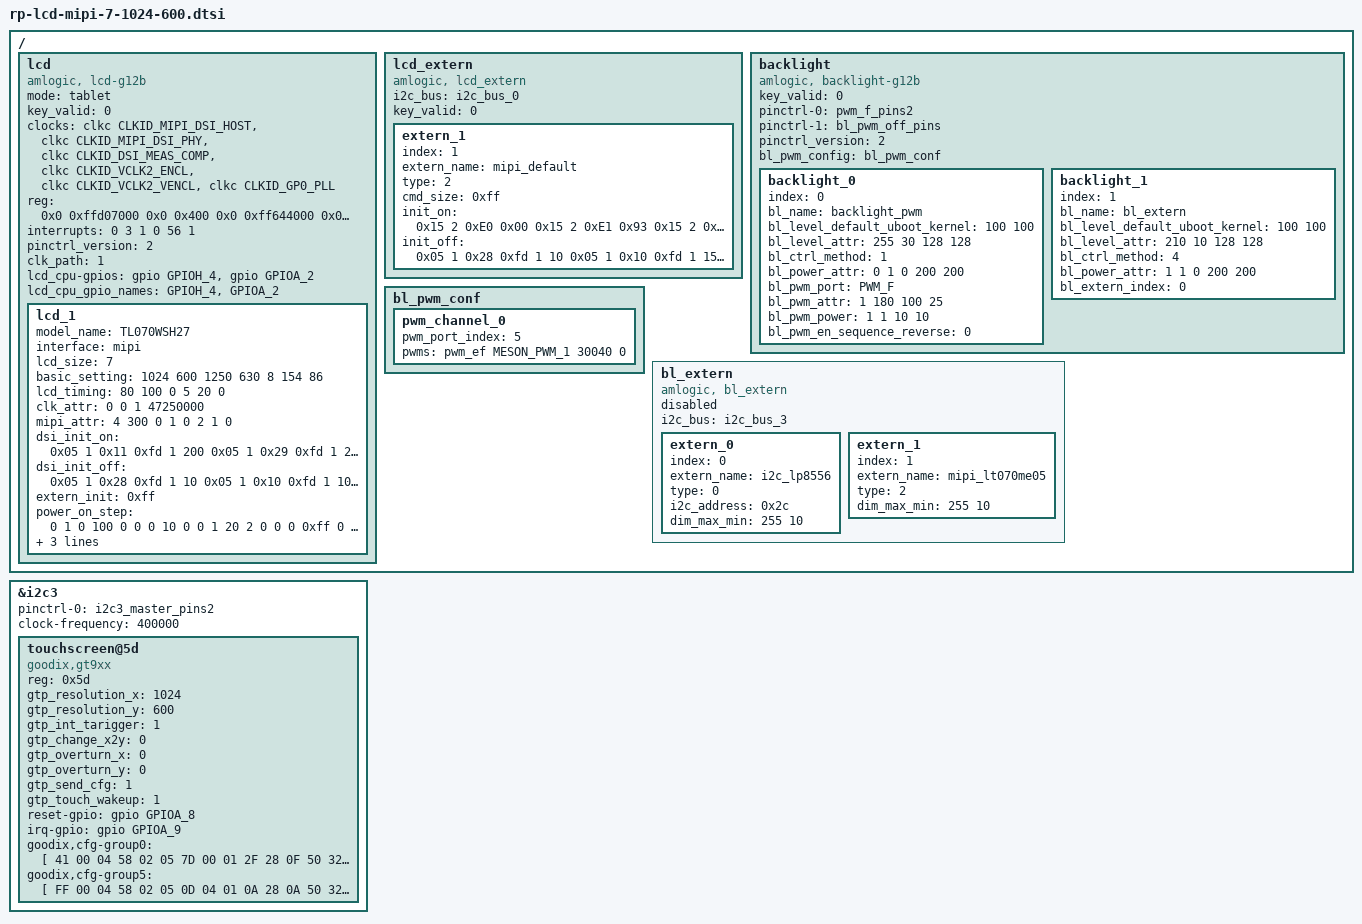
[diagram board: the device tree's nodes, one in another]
/*
 * arch/arm64/boot/dts/amlogic/mesong12b_skt-panel.dtsi
 *
 * Copyright (C) 2016 Amlogic, Inc. All rights reserved.
 *
 * This program is free software; you can redistribute it and/or modify
 * it under the terms of the GNU General Public License as published by
 * the Free Software Foundation; either version 2 of the License, or
 * (at your option) any later version.
 *
 * This program is distributed in the hope that it will be useful, but WITHOUT
 * ANY WARRANTY; without even the implied warranty of MERCHANTABILITY or
 * FITNESS FOR A PARTICULAR PURPOSE.  See the GNU General Public License for
 * more details.
 *
 */

/ {
	lcd{
		compatible = "amlogic, lcd-g12b";
		mode = "tablet";
		status = "okay";
		key_valid = <0>;
		clocks = <&clkc CLKID_MIPI_DSI_HOST
			&clkc CLKID_MIPI_DSI_PHY
			&clkc CLKID_DSI_MEAS_COMP
			&clkc CLKID_VCLK2_ENCL
			&clkc CLKID_VCLK2_VENCL
			&clkc CLKID_GP0_PLL>;
		clock-names = "dsi_host_gate",
			"dsi_phy_gate",
			"dsi_meas",
			"encl_top_gate",
			"encl_int_gate",
			"gp0_pll";
		reg = <0x0 0xffd07000 0x0 0x400    /* dsi_host */
			0x0 0xff644000 0x0 0x200>; /* dsi_phy */
		interrupts = <0 3 1
			0 56 1>;
		interrupt-names = "vsync","vsync2";
		pinctrl_version = <2>; /* for uboot */
		clk_path = <1>; /* default gp0 pll */

		/* power type:
		 *    (0=cpu_gpio, 1=pmu_gpio, 2=signal,3=extern, 0xff=ending)
		 * power index:
		 *    (point gpios_index, or extern_index,0xff=invalid)
		 * power value:(0=output low, 1=output high, 2=input)
		 * power delay:(unit in ms)
		 */
		lcd_cpu-gpios = <&gpio GPIOH_4 GPIO_ACTIVE_HIGH
				&gpio GPIOA_2 GPIO_ACTIVE_HIGH>;
		lcd_cpu_gpio_names = "GPIOH_4","GPIOA_2";


		lcd_1{
			model_name = "TL070WSH27";
			interface = "mipi";
			lcd_size = "7";
			basic_setting = <1024 600 /*h_active, v_active*/
				1250 630 /*h_period, v_period*/
				8 /*lcd_bits*/
				154 86>; /*screen_widht, screen_height*/
			lcd_timing = <80 100 0 /*hs_width, hs_bp, hs_pol*/
				5 20 0>; /*vs_width, vs_bp, vs_pol*/
			clk_attr = <0 /*fr_adj_type(0=clk, 1=htotal, 2=vtotal)*/
				0 /*clk_ss_level */
				1 /*clk_auto_generate*/
				47250000>; /*pixel_clk(unit in Hz)*/
			mipi_attr = <4 /*lane_num*/
				300 /*bit_rate_max(MHz)*/
				0 /*factor(*100, default 0 for auto)*/
				1 /*operation_mode_init(0=video, 1=command)*/
				0 /*operation_mode_display(0=video, 1=command)*/
				2 /*
				   *video_mode_type
				   *(0=sync_pulse,1=sync_event,2=burst)
				   */
				1 /*clk_always_hs(0=disable,1=enable)*/
				0>; /*phy_switch(0=auto,1=standard,2=slow)*/

			/* dsi_init: data_type, num, data... */
			dsi_init_on = <0x05 1 0x11
					0xfd 1 200  /*delay(ms)*/
					0x05 1 0x29
					0xfd 1 20   /*delay(ms)*/
					0xff 0>;    /*ending*/
			dsi_init_off = <0x05 1 0x28
					0xfd 1 10   /*delay(ms)*/
					0x05 1 0x10
					0xfd 1 10   /*delay(ms)*/
					0xff 0>;    /*ending*/
			extern_init = <0xff>; /*0xff for invalid*/

			/* power step: type, index, value, delay(ms) */
			power_on_step = <
				0 1 0 100
				0 0 0 10
				0 0 1 20
				2 0 0 0
				0xff 0 0 0>; /*ending*/
			power_off_step = <
				2 0 0 50
				0 0 0 10
				0 1 1 100
				0xff 0 0 0>; /*ending*/
			backlight_index = <0>;
		};
	};

	lcd_extern{
		compatible = "amlogic, lcd_extern";
		status = "okay";
		i2c_bus = "i2c_bus_0";
		key_valid = <0>;

		extern_1{
			index = <1>;
			extern_name = "mipi_default";/*P070ACB_FT*/
			status = "okay";
			type = <2>; /* 0=i2c, 1=spi, 2=mipi */
			cmd_size = <0xff>;
			init_on = <
				0x15 2 0xE0 0x00
				0x15 2 0xE1 0x93
				0x15 2 0xE2 0x65
				0x15 2 0xE3 0xF8
				0x15 2 0xE0 0x00
				0x15 2 0x70 0x10
				0x15 2 0x71 0x13
				0x15 2 0x72 0x06
				0x15 2 0x80 0x03
				0x15 2 0xE0 0x04
				0x15 2 0x2D 0x03
				0x15 2 0xE0 0x01
				0x15 2 0x00 0x00
				0x15 2 0x01 0xA0
				0x15 2 0x03 0x00
				0x15 2 0x04 0xA0
				0x15 2 0x17 0x00
				0x15 2 0x18 0xB1
				0x15 2 0x19 0x01
				0x15 2 0x1A 0x00
				0x15 2 0x1B 0xB1
				0x15 2 0x1C 0x01
				0x15 2 0x1F 0x3E
				0x15 2 0x20 0x2D
				0x15 2 0x21 0x2D
				0x15 2 0x22 0x0E
				0x15 2 0x37 0x19
				0x15 2 0x38 0x05
				0x15 2 0x39 0x08
				0x15 2 0x3A 0x12
				0x15 2 0x3C 0x78
				0x15 2 0x3E 0x80
				0x15 2 0x3F 0x80
				0x15 2 0x40 0x06
				0x15 2 0x41 0xA0
				0x15 2 0x55 0x01
				0x15 2 0x56 0x01
				0x15 2 0x57 0x69
				0x15 2 0x58 0x0A
				0x15 2 0x59 0x0A
				0x15 2 0x5A 0x28
				0x15 2 0x5B 0x19
				0x15 2 0x5D 0x7C
				0x15 2 0x5E 0x65
				0x15 2 0x5F 0x53
				0x15 2 0x60 0x48
				0x15 2 0x61 0x43
				0x15 2 0x62 0x35
				0x15 2 0x63 0x39
				0x15 2 0x64 0x23
				0x15 2 0x65 0x3D
				0x15 2 0x66 0x3C
				0x15 2 0x67 0x3D
				0x15 2 0x68 0x5A
				0x15 2 0x69 0x46
				0x15 2 0x6A 0x57
				0x15 2 0x6B 0x4B
				0x15 2 0x6C 0x49
				0x15 2 0x6D 0x2F
				0x15 2 0x6E 0x03
				0x15 2 0x6F 0x00
				0x15 2 0x70 0x7C
				0x15 2 0x71 0x65
				0x15 2 0x72 0x53
				0x15 2 0x73 0x48
				0x15 2 0x74 0x43
				0x15 2 0x75 0x35
				0x15 2 0x76 0x39
				0x15 2 0x77 0x23
				0x15 2 0x78 0x3D
				0x15 2 0x79 0x3C
				0x15 2 0x7A 0x3D
				0x15 2 0x7B 0x5A
				0x15 2 0x7C 0x46
				0x15 2 0x7D 0x57
				0x15 2 0x7E 0x4B
				0x15 2 0x7F 0x49
				0x15 2 0x80 0x2F
				0x15 2 0x81 0x03
				0x15 2 0x82 0x00
				0x15 2 0xE0 0x02
				0x15 2 0x00 0x47
				0x15 2 0x01 0x47
				0x15 2 0x02 0x45
				0x15 2 0x03 0x45
				0x15 2 0x04 0x4B
				0x15 2 0x05 0x4B
				0x15 2 0x06 0x49
				0x15 2 0x07 0x49
				0x15 2 0x08 0x41
				0x15 2 0x09 0x1F
				0x15 2 0x0A 0x1F
				0x15 2 0x0B 0x1F
				0x15 2 0x0C 0x1F
				0x15 2 0x0D 0x1F
				0x15 2 0x0E 0x1F
				0x15 2 0x0F 0x43
				0x15 2 0x10 0x1F
				0x15 2 0x11 0x1F
				0x15 2 0x12 0x1F
				0x15 2 0x13 0x1F
				0x15 2 0x14 0x1F
				0x15 2 0x15 0x1F
				0x15 2 0x16 0x46
				0x15 2 0x17 0x46
				0x15 2 0x18 0x44
				0x15 2 0x19 0x44
				0x15 2 0x1A 0x4A
				0x15 2 0x1B 0x4A
				0x15 2 0x1C 0x48
				0x15 2 0x1D 0x48
				0x15 2 0x1E 0x40
				0x15 2 0x1F 0x1F
				0x15 2 0x20 0x1F
				0x15 2 0x21 0x1F
				0x15 2 0x22 0x1F
				0x15 2 0x23 0x1F
				0x15 2 0x24 0x1F
				0x15 2 0x25 0x42
				0x15 2 0x26 0x1F
				0x15 2 0x27 0x1F
				0x15 2 0x28 0x1F
				0x15 2 0x29 0x1F
				0x15 2 0x2A 0x1F
				0x15 2 0x2B 0x1F
				0x15 2 0x2C 0x11
				0x15 2 0x2D 0x0F
				0x15 2 0x2E 0x0D
				0x15 2 0x2F 0x0B
				0x15 2 0x30 0x09
				0x15 2 0x31 0x07
				0x15 2 0x32 0x05
				0x15 2 0x33 0x18
				0x15 2 0x34 0x17
				0x15 2 0x35 0x1F
				0x15 2 0x36 0x01
				0x15 2 0x37 0x1F
				0x15 2 0x38 0x1F
				0x15 2 0x39 0x1F
				0x15 2 0x3A 0x1F
				0x15 2 0x3B 0x1F
				0x15 2 0x3C 0x1F
				0x15 2 0x3D 0x1F
				0x15 2 0x3E 0x1F
				0x15 2 0x3F 0x13
				0x15 2 0x40 0x1F
				0x15 2 0x41 0x1F
				0x15 2 0x42 0x10
				0x15 2 0x43 0x0E
				0x15 2 0x44 0x0C
				0x15 2 0x45 0x0A
				0x15 2 0x46 0x08
				0x15 2 0x47 0x06
				0x15 2 0x48 0x04
				0x15 2 0x49 0x18
				0x15 2 0x4A 0x17
				0x15 2 0x4B 0x1F
				0x15 2 0x4C 0x00
				0x15 2 0x4D 0x1F
				0x15 2 0x4E 0x1F
				0x15 2 0x4F 0x1F
				0x15 2 0x50 0x1F
				0x15 2 0x51 0x1F
				0x15 2 0x52 0x1F
				0x15 2 0x53 0x1F
				0x15 2 0x54 0x1F
				0x15 2 0x55 0x12
				0x15 2 0x56 0x1F
				0x15 2 0x57 0x1F
				0x15 2 0x58 0x40
				0x15 2 0x59 0x00
				0x15 2 0x5A 0x00
				0x15 2 0x5B 0x30
				0x15 2 0x5C 0x03
				0x15 2 0x5D 0x30
				0x15 2 0x5E 0x01
				0x15 2 0x5F 0x02
				0x15 2 0x60 0x00
				0x15 2 0x61 0x01
				0x15 2 0x62 0x02
				0x15 2 0x63 0x03
				0x15 2 0x64 0x6B
				0x15 2 0x65 0x00
				0x15 2 0x66 0x00
				0x15 2 0x67 0x73
				0x15 2 0x68 0x05
				0x15 2 0x69 0x06
				0x15 2 0x6A 0x6B
				0x15 2 0x6B 0x08
				0x15 2 0x6C 0x00
				0x15 2 0x6D 0x04
				0x15 2 0x6E 0x04
				0x15 2 0x6F 0x88
				0x15 2 0x70 0x00
				0x15 2 0x71 0x00
				0x15 2 0x72 0x06
				0x15 2 0x73 0x7B
				0x15 2 0x74 0x00
				0x15 2 0x75 0x07
				0x15 2 0x76 0x00
				0x15 2 0x77 0x5D
				0x15 2 0x78 0x17
				0x15 2 0x79 0x1F
				0x15 2 0x7A 0x00
				0x15 2 0x7B 0x00
				0x15 2 0x7C 0x00
				0x15 2 0x7D 0x03
				0x15 2 0x7E 0x7B
				0x15 2 0xE0 0x01
				0x15 2 0x0E 0x01
				0x15 2 0xE0 0x03
				0x15 2 0x98 0x2F
				0x15 2 0xE0 0x04
				0x15 2 0x09 0x10
				0x15 2 0x2B 0x2B
				0x15 2 0x2E 0x44
				0x15 2 0xE0 0x00
				0x15 2 0xE6 0x02
				0x15 2 0xE7 0x02

				0x05 1 0x11  /* display on */
				0xfd 1 200

				0x05 1 0x29 /* display on */
				0xfd 1 200
				0xFF 0>; /*ending*/
			init_off = <
				0x05 1 0x28 /* display off */
				0xfd 1 10   /* delay 10ms */
				0x05 1 0x10 /* sleep in */
				0xfd 1 150  /* delay 150ms */
				0xff 0>;    /*ending*/
		};

	};

	backlight{
		compatible = "amlogic, backlight-g12b";
		status = "okay";
		key_valid = <0>;
		pinctrl-names = "pwm_on","pwm_off";
		pinctrl-0 = <&pwm_f_pins2>;
		pinctrl-1 = <&bl_pwm_off_pins>;
		pinctrl_version = <2>; /* for uboot */
		bl_pwm_config = <&bl_pwm_conf>;
//		bl-gpios = <&gpio GPIOH_4 GPIO_ACTIVE_HIGH
//			&gpio GPIOH_5 GPIO_ACTIVE_HIGH>;
//		bl_gpio_names = "GPIOH_4","GPIOH_5";


//		bl-gpios = <&gpio GPIOH_5 GPIO_ACTIVE_HIGH>;
//		bl_gpio_names = "GPIOH_5";

		/* pwm port: PWM_A, PWM_B, PWM_C, PWM_D, PWM_E, PWM_F, PWM_VS*/
		/* power index:(point gpios_index, 0xff=invalid)
		 * power value:(0=output low, 1=output high, 2=input)
		 * power delay:(unit in ms)
		 */

		backlight_0{
			index = <0>;
			bl_name = "backlight_pwm";
			bl_level_default_uboot_kernel = <100 100>;
			bl_level_attr = <255 30 /*max, min*/
				128 128>; /*mid, mid_mapping*/
			bl_ctrl_method = <1>; /* 1=pwm, 2=pwm_combo, 4=extern */
			bl_power_attr = <0 /*en_gpio_index*/
				1 0 /*on_value, off_value*/
				200 200>; /*on_delay(ms), off_delay(ms)*/
			bl_pwm_port = "PWM_F";
			bl_pwm_attr = <1 /*pwm_method*/
				180 /*pwm_freq(pwm:Hz, pwm_vs:multiple of vs)*/
				100 25>; /*duty_max(%), duty_min(%)*/
			bl_pwm_power = <1 1 /*pwm_gpio_index, pwm_gpio_off*/
				10 10>; /*pwm_on_delay(ms), pwm_off_delay(ms)*/
			bl_pwm_en_sequence_reverse = <0>; /* 1 for reverse */
		};
		backlight_1{
			index = <1>;
			bl_name = "bl_extern";
			bl_level_default_uboot_kernel = <100 100>;
			bl_level_attr = <210 10 /*max, min*/
				128 128>; /*mid, mid_mapping*/
			bl_ctrl_method = <4>; /*1=pwm, 2=pwm_combo, 4=extern*/
			bl_power_attr = <1 /*en_gpio_index*/
				1 0 /*on_value, off_value*/
				200 200>; /*on_delay(ms), off_delay(ms)*/
			bl_extern_index = <0>;
		};
	};
	bl_pwm_conf:bl_pwm_conf{
		pwm_channel_0 {
			pwm_port_index = <5>;
			pwms = <&pwm_ef MESON_PWM_1 30040 0>;
		};
	};

	bl_extern{
		compatible = "amlogic, bl_extern";
		status = "disabled";
		i2c_bus = "i2c_bus_3";

		extern_0{
			index = <0>;
			extern_name = "i2c_lp8556";
			type = <0>; /*0=i2c, 1=spi, 2=mipi*/
			i2c_address = <0x2c>; /*7bit i2c address*/
			dim_max_min = <255 10>;
		};

		extern_1{
			index = <1>;
			extern_name = "mipi_lt070me05";
			type = <2>; /*0=i2c, 1=spi, 2=mipi*/
			dim_max_min = <255 10>;
		};
	};
};/* end of panel */

&i2c3 {
        status = "okay";
        pinctrl-names = "default";
        pinctrl-0 = <&i2c3_master_pins2>;
        clock-frequency = <400000>;

        touchscreen@5d {
                compatible = "goodix,gt9xx";
                status = "okay";
                reg = <0x5d>;
		gtp_resolution_x = <1024>;
		gtp_resolution_y = <600>;
		gtp_int_tarigger = <1>;
		gtp_change_x2y = <0>;
		gtp_overturn_x = <0>;
		gtp_overturn_y = <0>;
		gtp_send_cfg = <1>;
		gtp_touch_wakeup = <1>;
                reset-gpio = <&gpio GPIOA_8 GPIO_ACTIVE_HIGH>;
                irq-gpio = <&gpio GPIOA_9 GPIO_ACTIVE_HIGH>;
				/* for old touchscreen sensor_id 0 */
                goodix,cfg-group0 = [
			                       41 00 04 58 02 05 7D 00 01 2F 28
								   0F 50 32 03 05 00 00 00 00 00 00
								   00 18 1A 1E 14 89 0D 0C 2C 2A 0C
								   08 00 00 00 82 03 1D 0A 32 05 0A
								   32 00 00 00 00 00 0B 1E 50 94 E5
								   02 08 00 00 04 A7 21 00 8B 28 00
								   73 31 00 62 3B 00 52 48 00 52 00
								   00 00 00 00 00 00 00 00 00 00 00
								   00 00 00 00 00 00 00 00 00 00 00
								   00 00 00 00 00 00 00 00 32 50 00
								   00 00 1C 1A 18 16 14 12 10 0E 0C
								   0A 08 06 04 02 00 00 00 00 00 00
								   00 00 00 00 00 00 00 00 00 00 2A
								   29 28 26 24 22 21 20 1F 1E 1D 18
								   16 14 13 12 10 0F 0C 0A 08 06 FF
								   FF FF FF 00 00 00 00 00 00 00 00
								   00 00 00 00 00 00 00 00 3B 01
								   ];
				/* for new touchscreen sensor_id 5 */
                goodix,cfg-group5 = [
									 FF 00 04 58 02 05 0D 04 01
									 0A 28 0A 50 32 03 05 00 00
									 00 00 00 00 08 00 00 00 00
									 8B 2B 0E 30 32 0F 0A 00 00
									 00 83 02 1D 00 00 00 00 00
									 03 03 32 00 00 00 24 60 94
									 C0 02 00 00 00 04 93 27 00
									 80 30 00 70 3B 00 65 47 00
									 5C 57 00 5C 00 00 00 00 00
									 00 00 00 00 00 00 00 00 00
									 00 00 00 00 00 00 00 00 00
									 00 00 00 00 00 00 00 00 00
									 00 00 00 00 1C 1A 18 16 14
									 12 10 0E 0C 0A 08 06 04 02
									 00 00 00 00 00 00 00 00 00
									 00 00 00 00 00 00 00 26 24
									 22 21 20 1F 1E 1D 1C 18 16
									 13 12 10 0F 0C 0A 08 06 04
									 02 00 FF FF FF FF 00 00 00
									 00 00 00 00 00 00 00 00 00
									 00 00 00 00 6A 01
									 ];

        };
};
